# STM32C071 register map
File version: 1.1
CPU: CM0+ r0p0, little endian, MPU, no FPU, 2 interrupt priority bits
Registers are 32-bit, read-write, reset 0x0 unless marked. A register's access mark holds for its fields unless they carry their own. Offsets are from the block's base; [hi:lo] are bit positions; {n}, {i} and the like mark numbered series.

## EXTI — EXTI address block description
Base 0x40021800
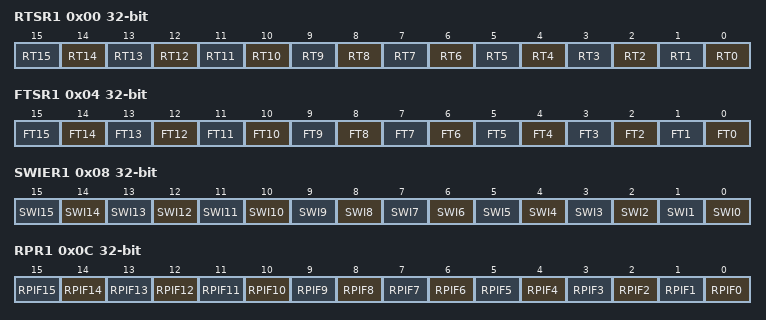
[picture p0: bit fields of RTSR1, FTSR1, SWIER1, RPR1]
0x00 RTSR1 — EXTI rising trigger selection register 1
  [n] RT{n} (n=0..15) — Rising trigger event configuration bit of configurable line x (x = 15 to 0) Each bit enables/disables the rising edge trigger for the event and interrupt on the corresponding line. Note: The configurable lines are edge triggered; no glitch must be generated on these inputs. If a rising edge on the configurable line occurs during writing of the register, the associated pending bit is not set. Rising edge trigger can be set for a line with falling edge trigger enabled. In this case, both edges generate a trigger.
0x04 FTSR1 — EXTI falling trigger selection register 1
  [n] FT{n} (n=0..15) — Falling trigger event configuration bit of configurable line x (x = 15 to 0). Each bit enables/disables the falling edge trigger for the event and interrupt on the corresponding line. The configurable lines are edge triggered; no glitch must be generated on these inputs. Note: If a falling edge on the configurable line occurs during writing of the register, the associated pending bit is not set. Falling edge trigger can be set for a line with rising edge trigger enabled. In this case, both edges generate a trigger.
0x08 SWIER1 — EXTI software interrupt event register 1
  [n] SWI{n} (n=0..15) — Software rising edge event trigger on line x (x = 15 to 0) Setting of any bit by software triggers a rising edge event on the corresponding line x, resulting in an interrupt, independently of EXTI_RTSR1 and EXTI_FTSR1 settings. The bits are automatically cleared by HW. Reading of any bit always returns 0.
0x0C RPR1 — EXTI rising edge pending register 1
  [n] RPIF{n} (n=0..15) — Rising edge event pending for configurable line x (x = 15 to 0) Each bit is set upon a rising edge event generated by hardware or by software (through the EXTI_SWIER1 register) on the corresponding line. Each bit is cleared by writing 1 into it.
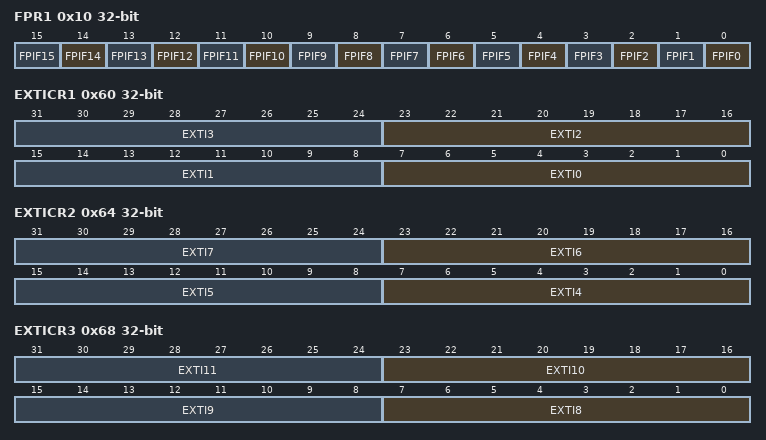
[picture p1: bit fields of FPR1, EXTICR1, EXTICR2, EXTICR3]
0x10 FPR1 — EXTI falling edge pending register 1
  [n] FPIF{n} (n=0..15) — Falling edge event pending for configurable line x (x = 15 to 0) Each bit is set upon a falling edge event generated by hardware or by software (through the EXTI_SWIER1 register) on the corresponding line. Each bit is cleared by writing 1 into it.
0x28 RTSR2 — EXTI rising trigger selection register 2
  [2] RT34 — Rising trigger event configuration bit of configurable line 34 Each bit enables/disables the rising edge trigger for the event and interrupt on the line 34. This configurable line is edge triggered; no glitch must be generated on this inputs. Note: If a rising edge on the configurable line occurs during writing of the register, the associated pending bit is not set. Rising edge trigger can be set for a line with falling edge trigger enabled. In this case, both edges generate a trigger.
0x2C FTSR2 — EXTI falling trigger selection register 2
  [2] FT34 — Falling trigger event configuration bit of configurable line 34. Each bit enables/disables the falling edge trigger for the event and interrupt on the line 34. The configurable lines are edge triggered; no glitch must be generated on these inputs. Note: If a falling edge on the configurable line occurs during writing of the register, the associated pending bit is not set. Falling edge trigger can be set for a line with rising edge trigger enabled. In this case, both edges generate a trigger.
0x30 SWIER2 — EXTI software interrupt event register 2
  [2] SWI34 — Software rising edge event trigger on line 34 Setting of any bit by software triggers a rising edge event on the line 34, resulting in an interrupt, independently of EXTI_RTSR2 and EXTI_FTSR2 settings. The bits are automatically cleared by HW. Reading of any bit always returns 0.
0x34 RPR2 — EXTI rising edge pending register 2
  [2] RPIF34 — Rising edge event pending for configurable line 34 Each bit is set upon a rising edge event generated by hardware or by software (through the EXTI_SWIER2 register) on the line 34. Each bit is cleared by writing 1 into it.
0x38 FPR2 — EXTI falling edge pending register 2
  [2] FPIF34 — Falling edge event pending for configurable line 34 Each bit is set upon a falling edge event generated by hardware or by software (through the EXTI_SWIER2 register) on the line 34. Each bit is cleared by writing 1 into it.
0x60 EXTICR1 — EXTI external interrupt selection register
  [8n+7:8n] EXTI{n} (n=0..3) — EXTI{n} GPIO port selection These bits are written by software to select the source input for EXTI{n} external interrupt. Others reserved
0x64 EXTICR2 — EXTI external interrupt selection register
  [8n-25:8n-32] EXTI{n} (n=4..7) — EXTI{n} GPIO port selection These bits are written by software to select the source input for EXTI{n} external interrupt. Others reserved
0x68 EXTICR3 — EXTI external interrupt selection register
  [8n-57:8n-64] EXTI{n} (n=8..11) — EXTI{n} GPIO port selection These bits are written by software to select the source input for EXTI{n} external interrupt. Others reserved
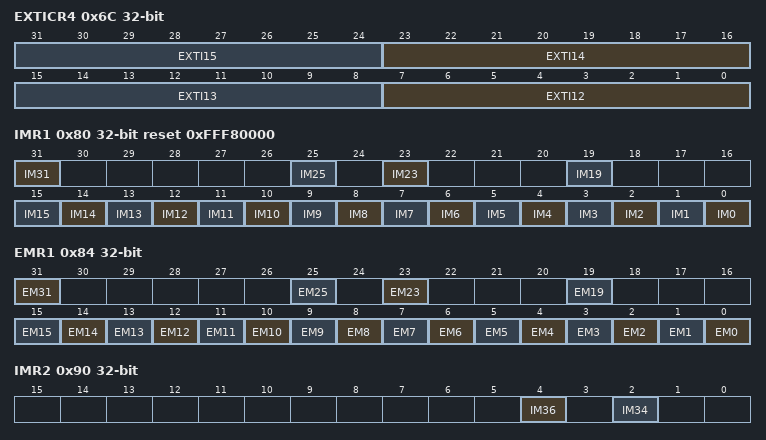
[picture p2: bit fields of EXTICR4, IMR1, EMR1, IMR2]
0x6C EXTICR4 — EXTI external interrupt selection register
  [8n-89:8n-96] EXTI{n} (n=12..15) — EXTI{n} GPIO port selection These bits are written by software to select the source input for EXTI{n} external interrupt. Others reserved
0x80 IMR1 reset 0xFFF80000 — EXTI CPU wakeup with interrupt mask register 1
  [31] IM31 — CPU wakeup with interrupt mask on line 31 Setting/clearing this bit unmasks/masks the CPU wakeup with interrupt, by an event on the corresponding line.
  [25] IM25 — CPU wakeup with interrupt mask on line 25 Setting/clearing each bit unmasks/masks the CPU wakeup with interrupt, by an event on the corresponding line.
  [23] IM23 — CPU wakeup with interrupt mask on line 23 Setting/clearing each bit unmasks/masks the CPU wakeup with interrupt, by an event on the corresponding line.
  [19] IM19 — CPU wakeup with interrupt mask on line 19 Setting/clearing this bit unmasks/masks the CPU wakeup with interrupt, by an event on the corresponding line.
  [n] IM{n} (n=0..15) — CPU wakeup with interrupt mask on line x (x = 15 to 0) Setting/clearing each bit unmasks/masks the CPU wakeup with interrupt, by an event on the corresponding line.
0x84 EMR1 — EXTI CPU wakeup with event mask register
  [31] EM31 — CPU wakeup with event generation mask on line 31 Setting/clearing this bit unmasks/masks the CPU wakeup with event generation on the corresponding line.
  [25] EM25 — CPU wakeup with event generation mask on line 25 Setting/clearing this bit unmasks/masks the CPU wakeup with event generation on the corresponding line.
  [23] EM23 — CPU wakeup with event generation mask on line 23 Setting/clearing this bit unmasks/masks the CPU wakeup with event generation on the corresponding line.
  [19] EM19 — CPU wakeup with event generation mask on line 19 Setting/clearing this bit unmasks/masks the CPU wakeup with event generation on the corresponding line.
  [n] EM{n} (n=0..15) — CPU wakeup with event generation mask on line x (x = 15 to 0) Setting/clearing each bit unmasks/masks the CPU wakeup with event generation on the corresponding line.
0x90 IMR2 — EXTI CPU wakeup with interrupt mask register 2
  [4] IM36 — CPU wake-up with interrupt mask on line 36
  [2] IM34 — CPU wakeup with interrupt mask on line 34 Setting/clearing the bit unmasks/masks the CPU wakeup with interrupt request from the line 34.
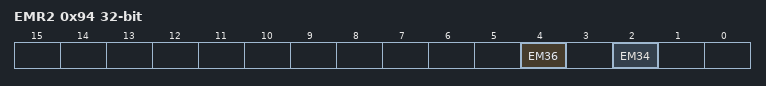
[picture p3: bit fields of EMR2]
0x94 EMR2 — EXTI CPU wakeup with event mask register 2
  [4] EM36 — CPU wake-up with event generation mask on line 36
  [2] EM34 — CPU wakeup with event generation mask on line 34 Setting/clearing this bit unmasks/masks the CPU wakeup with event generation on the line 34.
